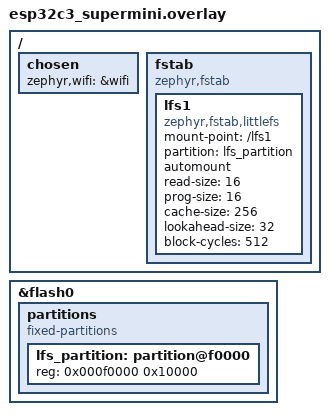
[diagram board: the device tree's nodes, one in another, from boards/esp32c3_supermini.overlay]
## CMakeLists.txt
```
cmake_minimum_required(VERSION 3.13.1)

find_package(Zephyr REQUIRED HINTS $ENV{ZEPHYR_BASE})

project(app)

target_sources(app PRIVATE src/main.c)
```

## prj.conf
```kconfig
CONFIG_MY_WIFI_CONNECTION=y
CONFIG_MY_WIFI_CONNECTION_SHELL=y
CONFIG_MY_WIFI_KEYS=y
CONFIG_MY_WIFI_KEYS_SHELL=y
CONFIG_LOG=y
CONFIG_MAIN_STACK_SIZE=8192
```

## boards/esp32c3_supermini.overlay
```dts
&flash0 {
    partitions {
        compatible = "fixed-partitions";
        #address-cells = <1>;
        #size-cells = <1>;

        lfs_partition: partition@f0000 {
            reg = <0x000f0000 0x10000>;
        };
    };
};

/ {
	chosen {
		zephyr,wifi = &wifi;
	};

    fstab {
        compatible = "zephyr,fstab";
        lfs1: lfs1 {
            compatible = "zephyr,fstab,littlefs";
            mount-point = "/lfs1";
            partition = <&lfs_partition>;
            automount;
            read-size = <16>;
            prog-size = <16>;
            cache-size = <256>;
            lookahead-size = <32>;
            block-cycles = <512>;
        };
    };
};
```

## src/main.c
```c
#include <zephyr/kernel.h>

int main() { return 0; }
```
